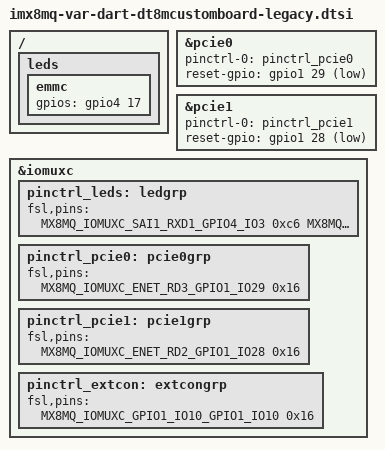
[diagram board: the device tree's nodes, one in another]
// SPDX-License-Identifier: (GPL-2.0 OR MIT)
/*
 * Copyright 2017 NXP
 * Copyright (C) 2017-2018 Pengutronix, Lucas Stach <kernel@pengutronix.de>
 * Copyright 2018-2021 Variscite Ltd.
 */

#include "imx8mq-var-dart-dt8mcustomboard.dtsi"

/ {

	leds {
		emmc {
			gpios = <&gpio4 17 GPIO_ACTIVE_HIGH>;
		};
	};

	/delete-node/ extcon_usb1;
};

&pcie0 {
	pinctrl-names = "default";
	pinctrl-0 = <&pinctrl_pcie0>;
	reset-gpio = <&gpio1 29 GPIO_ACTIVE_LOW>;
};

&pcie1 {
	pinctrl-names = "default";
	pinctrl-0 = <&pinctrl_pcie1>;
	reset-gpio = <&gpio1 28 GPIO_ACTIVE_LOW>;
};

&iomuxc {
	pinctrl_leds: ledgrp {
		fsl,pins = <
			MX8MQ_IOMUXC_SAI1_RXD1_GPIO4_IO3		0xc6
			MX8MQ_IOMUXC_SAI1_TXD2_GPIO4_IO14		0xc6
			MX8MQ_IOMUXC_SAI1_RXD2_GPIO4_IO4		0xc6
			MX8MQ_IOMUXC_SAI1_TXD5_GPIO4_IO17		0xc6
		>;
	};
	pinctrl_pcie0: pcie0grp {
		fsl,pins = <
			MX8MQ_IOMUXC_ENET_RD3_GPIO1_IO29		0x16
		>;
	};

	pinctrl_pcie1: pcie1grp {
		fsl,pins = <
			MX8MQ_IOMUXC_ENET_RD2_GPIO1_IO28		0x16
		>;
	};

	pinctrl_extcon: extcongrp {
		fsl,pins = <
			MX8MQ_IOMUXC_GPIO1_IO10_GPIO1_IO10		0x16
		>;
	};
};
